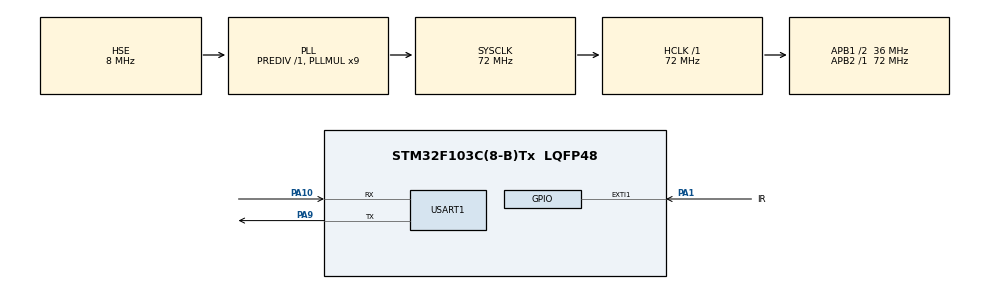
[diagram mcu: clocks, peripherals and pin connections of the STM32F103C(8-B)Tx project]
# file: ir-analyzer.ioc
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Mcu.Family=STM32F1
Mcu.Name=STM32F103C(8-B)Tx
Mcu.Package=LQFP48
NVIC.EXTI1_IRQn=true\:0\:0\:false\:false\:true\:true
NVIC.PriorityGroup=NVIC_PRIORITYGROUP_4
NVIC.TIM1_CC_IRQn=true\:0\:0\:false\:false\:true\:true
PA1.GPIO_Label=IR
PA1.GPIO_ModeDefaultEXTI=GPIO_MODE_IT_RISING_FALLING
PA1.GPIO_PuPd=GPIO_PULLUP
PA1.Signal=GPXTI1
PA10.Mode=Asynchronous
PA10.Signal=USART1_RX
PA13.Mode=Serial_Wire
PA13.Signal=SYS_JTMS-SWDIO
PA14.Mode=Serial_Wire
PA14.Signal=SYS_JTCK-SWCLK
PA9.Mode=Asynchronous
PA9.Signal=USART1_TX
PD0-OSC_IN.Mode=HSE-External-Oscillator
PD0-OSC_IN.Signal=RCC_OSC_IN
PD1-OSC_OUT.Mode=HSE-External-Oscillator
PD1-OSC_OUT.Signal=RCC_OSC_OUT
ProjectManager.HeapSize=0x200
ProjectManager.StackSize=0x400
ProjectManager.TargetToolchain=SW4STM32
RCC.AHBFreq_Value=72000000
RCC.APB1CLKDivider=RCC_HCLK_DIV2
RCC.APB1Freq_Value=36000000
RCC.APB1TimFreq_Value=72000000
RCC.APB2Freq_Value=72000000
RCC.APB2TimFreq_Value=72000000
RCC.HCLKFreq_Value=72000000
RCC.PLLMUL=RCC_PLL_MUL9
RCC.PLLSourceVirtual=RCC_PLLSOURCE_HSE
RCC.SYSCLKFreq_VALUE=72000000
RCC.SYSCLKSource=RCC_SYSCLKSOURCE_PLLCLK
RCC.USBFreq_Value=72000000
TIM1.Channel-Output\ Compare1\ No\ Output=TIM_CHANNEL_1
TIM1.Period=100
TIM1.Prescaler=72
TIM1.Pulse-Output\ Compare1\ No\ Output=65535
USART1.VirtualMode=VM_ASYNC
VP_TIM1_VS_no_output1.Mode=Output Compare1 No Output
board=custom

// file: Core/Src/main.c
/**
  ******************************************************************************
  * @file           : main.c
  * @brief          : Main program body
  ******************************************************************************
  ** This notice applies to any and all portions of this file
  * that are not between comment pairs USER CODE BEGIN and
  * USER CODE END. Other portions of this file, whether
  * inserted by the user or by software development tools
  * are owned by their respective copyright owners.
  *
  * COPYRIGHT(c) 2021 STMicroelectronics
  *
  * Redistribution and use in source and binary forms, with or without modification,
  * are permitted provided that the following conditions are met:
  *   1. Redistributions of source code must retain the above copyright notice,
  *      this list of conditions and the following disclaimer.
  *   2. Redistributions in binary form must reproduce the above copyright notice,
  *      this list of conditions and the following disclaimer in the documentation
  *      and/or other materials provided with the distribution.
  *   3. Neither the name of STMicroelectronics nor the names of its contributors
  *      may be used to endorse or promote products derived from this software
  *      without specific prior written permission.
  *
  * THIS SOFTWARE IS PROVIDED BY THE COPYRIGHT HOLDERS AND CONTRIBUTORS "AS IS"
  * AND ANY EXPRESS OR IMPLIED WARRANTIES, INCLUDING, BUT NOT LIMITED TO, THE
  * IMPLIED WARRANTIES OF MERCHANTABILITY AND FITNESS FOR A PARTICULAR PURPOSE ARE
  * DISCLAIMED. IN NO EVENT SHALL THE COPYRIGHT HOLDER OR CONTRIBUTORS BE LIABLE
  * FOR ANY DIRECT, INDIRECT, INCIDENTAL, SPECIAL, EXEMPLARY, OR CONSEQUENTIAL
  * DAMAGES (INCLUDING, BUT NOT LIMITED TO, PROCUREMENT OF SUBSTITUTE GOODS OR
  * SERVICES; LOSS OF USE, DATA, OR PROFITS; OR BUSINESS INTERRUPTION) HOWEVER
  * CAUSED AND ON ANY THEORY OF LIABILITY, WHETHER IN CONTRACT, STRICT LIABILITY,
  * OR TORT (INCLUDING NEGLIGENCE OR OTHERWISE) ARISING IN ANY WAY OUT OF THE USE
  * OF THIS SOFTWARE, EVEN IF ADVISED OF THE POSSIBILITY OF SUCH DAMAGE.
  *
  ******************************************************************************
  */
#include "main.h"
#include "stm32f1xx_hal.h"

/* USER CODE BEGIN Includes */
#define MAX_PULSES 128
#include "stdlib.h"
#include "string.h"
/* USER CODE END Includes */

TIM_HandleTypeDef htim1;

UART_HandleTypeDef huart1;

/* USER CODE BEGIN PV */
/* Private variables ---------------------------------------------------------*/
uint8_t recording = 0;
uint8_t ready = 0;
uint16_t pulses[MAX_PULSES + 1];
uint8_t current_pulse = 0;
uint32_t timer = 0;
uint8_t outbuf[128];
/* USER CODE END PV */

void SystemClock_Config(void);
static void MX_GPIO_Init(void);
static void MX_TIM1_Init(void);
static void MX_USART1_UART_Init(void);

/* USER CODE BEGIN PFP */
/* Private function prototypes -----------------------------------------------*/
void HAL_GPIO_EXTI_Callback(uint16_t pin) {

  if (GPIO_PIN_RESET == HAL_GPIO_ReadPin(IR_GPIO_Port, IR_Pin) && !recording) {
    recording = 1;
    timer = 0;
    current_pulse = 0;
    return;
  }

  if (recording && current_pulse < MAX_PULSES) {
    pulses[current_pulse] = timer;
    timer = 0;
    current_pulse++;
  }

}

void HAL_TIM_OC_DelayElapsedCallback(TIM_HandleTypeDef *htim) {
  if (recording) {
    timer++;
    if (timer > 1000) {
      recording = 0;
      timer = 0;
      ready = 1;
    }
  }
}

/* USER CODE END PFP */

int main(void)
{

  /* MCU Configuration----------------------------------------------------------*/

  /* Reset of all peripherals, Initializes the Flash interface and the Systick. */
  HAL_Init();

  /* Configure the system clock */
  SystemClock_Config();

  /* Initialize all configured peripherals */
  MX_GPIO_Init();
  MX_TIM1_Init();
  MX_USART1_UART_Init();
  /* USER CODE BEGIN 2 */
  HAL_TIM_OC_Start_IT(&htim1, TIM_CHANNEL_1);
  /* USER CODE END 2 */

  /* Infinite loop */
  /* USER CODE BEGIN WHILE */
#pragma clang diagnostic push
#pragma ide diagnostic ignored "EndlessLoop"
  while (1)
  {
    if (ready) {
      for (uint8_t i = 0; i < current_pulse; i++) {
        itoa(pulses[i], outbuf, 10);
        HAL_UART_Transmit(&huart1, outbuf, strlen(outbuf), 10);
        HAL_UART_Transmit(&huart1, ", ", 2, 10);
      }
      HAL_UART_Transmit(&huart1, "\r\n", 2, 10);
      ready = 0;
    }
  /* USER CODE END WHILE */

  /* USER CODE BEGIN 3 */

  }
#pragma clang diagnostic pop
  /* USER CODE END 3 */

}

void SystemClock_Config(void)
{

  RCC_OscInitTypeDef RCC_OscInitStruct;
  RCC_ClkInitTypeDef RCC_ClkInitStruct;

    /**Initializes the CPU, AHB and APB busses clocks
    */
  RCC_OscInitStruct.OscillatorType = RCC_OSCILLATORTYPE_HSE;
  RCC_OscInitStruct.HSEState = RCC_HSE_ON;
  RCC_OscInitStruct.HSEPredivValue = RCC_HSE_PREDIV_DIV1;
  RCC_OscInitStruct.HSIState = RCC_HSI_ON;
  RCC_OscInitStruct.PLL.PLLState = RCC_PLL_ON;
  RCC_OscInitStruct.PLL.PLLSource = RCC_PLLSOURCE_HSE;
  RCC_OscInitStruct.PLL.PLLMUL = RCC_PLL_MUL9;
  if (HAL_RCC_OscConfig(&RCC_OscInitStruct) != HAL_OK)
  {
    _Error_Handler(__FILE__, __LINE__);
  }

    /**Initializes the CPU, AHB and APB busses clocks
    */
  RCC_ClkInitStruct.ClockType = RCC_CLOCKTYPE_HCLK|RCC_CLOCKTYPE_SYSCLK
                              |RCC_CLOCKTYPE_PCLK1|RCC_CLOCKTYPE_PCLK2;
  RCC_ClkInitStruct.SYSCLKSource = RCC_SYSCLKSOURCE_PLLCLK;
  RCC_ClkInitStruct.AHBCLKDivider = RCC_SYSCLK_DIV1;
  RCC_ClkInitStruct.APB1CLKDivider = RCC_HCLK_DIV2;
  RCC_ClkInitStruct.APB2CLKDivider = RCC_HCLK_DIV1;

  if (HAL_RCC_ClockConfig(&RCC_ClkInitStruct, FLASH_LATENCY_2) != HAL_OK)
  {
    _Error_Handler(__FILE__, __LINE__);
  }

    /**Configure the Systick interrupt time
    */
  HAL_SYSTICK_Config(HAL_RCC_GetHCLKFreq()/1000);

    /**Configure the Systick
    */
  HAL_SYSTICK_CLKSourceConfig(SYSTICK_CLKSOURCE_HCLK);

  /* SysTick_IRQn interrupt configuration */
  HAL_NVIC_SetPriority(SysTick_IRQn, 0, 0);
}

/* TIM1 init function */
static void MX_TIM1_Init(void)
{

  TIM_MasterConfigTypeDef sMasterConfig;
  TIM_OC_InitTypeDef sConfigOC;
  TIM_BreakDeadTimeConfigTypeDef sBreakDeadTimeConfig;

  htim1.Instance = TIM1;
  htim1.Init.Prescaler = 72;
  htim1.Init.CounterMode = TIM_COUNTERMODE_UP;
  htim1.Init.Period = 100;
  htim1.Init.ClockDivision = TIM_CLOCKDIVISION_DIV1;
  htim1.Init.RepetitionCounter = 0;
  htim1.Init.AutoReloadPreload = TIM_AUTORELOAD_PRELOAD_DISABLE;
  if (HAL_TIM_OC_Init(&htim1) != HAL_OK)
  {
    _Error_Handler(__FILE__, __LINE__);
  }

  sMasterConfig.MasterOutputTrigger = TIM_TRGO_RESET;
  sMasterConfig.MasterSlaveMode = TIM_MASTERSLAVEMODE_DISABLE;
  if (HAL_TIMEx_MasterConfigSynchronization(&htim1, &sMasterConfig) != HAL_OK)
  {
    _Error_Handler(__FILE__, __LINE__);
  }

  sConfigOC.OCMode = TIM_OCMODE_TIMING;
  sConfigOC.Pulse = 65535;
  sConfigOC.OCPolarity = TIM_OCPOLARITY_HIGH;
  sConfigOC.OCNPolarity = TIM_OCNPOLARITY_HIGH;
  sConfigOC.OCFastMode = TIM_OCFAST_DISABLE;
  sConfigOC.OCIdleState = TIM_OCIDLESTATE_RESET;
  sConfigOC.OCNIdleState = TIM_OCNIDLESTATE_RESET;
  if (HAL_TIM_OC_ConfigChannel(&htim1, &sConfigOC, TIM_CHANNEL_1) != HAL_OK)
  {
    _Error_Handler(__FILE__, __LINE__);
  }

  sBreakDeadTimeConfig.OffStateRunMode = TIM_OSSR_DISABLE;
  sBreakDeadTimeConfig.OffStateIDLEMode = TIM_OSSI_DISABLE;
  sBreakDeadTimeConfig.LockLevel = TIM_LOCKLEVEL_OFF;
  sBreakDeadTimeConfig.DeadTime = 0;
  sBreakDeadTimeConfig.BreakState = TIM_BREAK_DISABLE;
  sBreakDeadTimeConfig.BreakPolarity = TIM_BREAKPOLARITY_HIGH;
  sBreakDeadTimeConfig.AutomaticOutput = TIM_AUTOMATICOUTPUT_DISABLE;
  if (HAL_TIMEx_ConfigBreakDeadTime(&htim1, &sBreakDeadTimeConfig) != HAL_OK)
  {
    _Error_Handler(__FILE__, __LINE__);
  }

}

/* USART1 init function */
static void MX_USART1_UART_Init(void)
{

  huart1.Instance = USART1;
  huart1.Init.BaudRate = 115200;
  huart1.Init.WordLength = UART_WORDLENGTH_8B;
  huart1.Init.StopBits = UART_STOPBITS_1;
  huart1.Init.Parity = UART_PARITY_NONE;
  huart1.Init.Mode = UART_MODE_TX_RX;
  huart1.Init.HwFlowCtl = UART_HWCONTROL_NONE;
  huart1.Init.OverSampling = UART_OVERSAMPLING_16;
  if (HAL_UART_Init(&huart1) != HAL_OK)
  {
    _Error_Handler(__FILE__, __LINE__);
  }

}

/** Configure pins as
        * Analog
        * Input
        * Output
        * EVENT_OUT
        * EXTI
*/
static void MX_GPIO_Init(void)
{

  GPIO_InitTypeDef GPIO_InitStruct;

  /* GPIO Ports Clock Enable */
  __HAL_RCC_GPIOD_CLK_ENABLE();
  __HAL_RCC_GPIOA_CLK_ENABLE();

  /*Configure GPIO pin : IR_Pin */
  GPIO_InitStruct.Pin = IR_Pin;
  GPIO_InitStruct.Mode = GPIO_MODE_IT_RISING_FALLING;
  GPIO_InitStruct.Pull = GPIO_PULLUP;
  HAL_GPIO_Init(IR_GPIO_Port, &GPIO_InitStruct);

  /* EXTI interrupt init*/
  HAL_NVIC_SetPriority(EXTI1_IRQn, 0, 0);
  HAL_NVIC_EnableIRQ(EXTI1_IRQn);

}

void _Error_Handler(char *file, int line)
{
  while(1)
  {
  }
}

/************************ (C) COPYRIGHT STMicroelectronics *****END OF FILE****/
